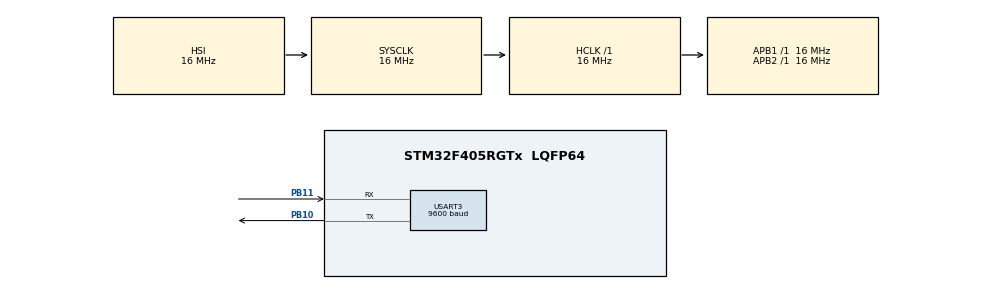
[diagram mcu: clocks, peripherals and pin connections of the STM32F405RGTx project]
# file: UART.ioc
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Mcu.Family=STM32F4
Mcu.Name=STM32F405RGTx
Mcu.Package=LQFP64
NVIC.PriorityGroup=NVIC_PRIORITYGROUP_4
NVIC.USART3_IRQn=true\:0\:0\:false\:false\:true\:true\:true\:true
PA13.Mode=Serial_Wire
PA13.Signal=SYS_JTMS-SWDIO
PA14.Mode=Serial_Wire
PA14.Signal=SYS_JTCK-SWCLK
PB10.Mode=Asynchronous
PB10.Signal=USART3_TX
PB11.Mode=Asynchronous
PB11.Signal=USART3_RX
ProjectManager.HeapSize=0x200
ProjectManager.StackSize=0x400
ProjectManager.TargetToolchain=STM32CubeIDE
RCC.AHBFreq_Value=16000000
RCC.APB1Freq_Value=16000000
RCC.APB2Freq_Value=16000000
RCC.CortexFreq_Value=16000000
RCC.HSE_VALUE=25000000
RCC.HSI_VALUE=16000000
RCC.LSE_VALUE=32768
RCC.SYSCLKFreq_VALUE=16000000
RCC.VCOOutputFreq_Value=192000000
USART3.BaudRate=9600
USART3.VirtualMode=VM_ASYNC
board=custom

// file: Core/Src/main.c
/* USER CODE BEGIN Header */
/**
 ******************************************************************************
 * @file           : main.c
 * @brief          : Main program body
 ******************************************************************************
 * @attention
 *
 * Copyright (c) 2022 STMicroelectronics.
 * All rights reserved.
 *
 * This software is licensed under terms that can be found in the LICENSE file
 * in the root directory of this software component.
 * If no LICENSE file comes with this software, it is provided AS-IS.
 *
 ******************************************************************************
 */
/* USER CODE END Header */
#include "main.h"

/* USER CODE BEGIN Includes */
uint8_t u8_RxBuff[20];
uint8_t u8_RxData;
uint8_t u8_TxBuff[20] = "Running...";
uint8_t _rxIndex;
uint16_t Tx_Flag = 0;
/* USER CODE END Includes */

UART_HandleTypeDef huart3;

/* USER CODE BEGIN PV */
#ifdef __GNUC__
/* With GCC/RAISONANCE, small printf (option LD Linker->Libraries->Small printf
 set to 'Yes') calls __io_putchar() */
#define PUTCHAR_PROTOTYPE int __io_putchar(int ch)
#else
 #define PUTCHAR_PROTOTYPE int fputc(int ch, FILE *f)
#endif /* __GNUC__ */

/**
 * @brief Retargets the C library printf function to the USART.
 * @param None
 * @retval None
 */
PUTCHAR_PROTOTYPE
{
  /* Place your implementation of fputc here */
  /* e.g. write a character to the USART */
  HAL_UART_Transmit(&huart3, (uint8_t*) &ch, 1, 100);
  return ch;
}

/* USER CODE END PV */

void SystemClock_Config(void);
static void MX_GPIO_Init(void);
static void MX_USART3_UART_Init(void);

/* USER CODE BEGIN 0 */
void HAL_UART_RxCpltCallback(UART_HandleTypeDef *huart)
{
  /* Prevent unused argument(s) compilation warning */
  UNUSED(huart);
//  if(huart->Instance == USART3)
  {
	  if(u8_RxData != 13)
	  {
		  u8_RxBuff[_rxIndex++] = u8_RxData;
	  }
	  else if(u8_RxData == 13)
	  {
		  _rxIndex = 0;
		  Tx_Flag = 1;
	  }
	  HAL_UART_Receive_IT(&huart3, &u8_RxData, 1);
  }
  /* NOTE: This function should not be modified, when the callback is needed,
           the HAL_UART_RxCpltCallback could be implemented in the user file
   */

}
/* USER CODE END 0 */

int main(void)
{

  /* MCU Configuration--------------------------------------------------------*/

  /* Reset of all peripherals, Initializes the Flash interface and the Systick. */
  HAL_Init();

  /* Configure the system clock */
  SystemClock_Config();

  /* Initialize all configured peripherals */
  MX_GPIO_Init();
  MX_USART3_UART_Init();
  /* USER CODE BEGIN 2 */
  HAL_UART_Transmit(&huart3, u8_TxBuff, sizeof(u8_TxBuff), 100);
  HAL_UART_Receive_IT(&huart3, &u8_RxData, 1);
  /* USER CODE END 2 */

  /* Infinite loop */
	while (1) {

    /* USER CODE BEGIN 3 */
		if(Tx_Flag)
		{
			for(int i=0; i< 20; i++)
			{
				u8_RxBuff[i] = u8_RxBuff[i];

			}
			HAL_UART_Transmit(&huart3, u8_TxBuff, sizeof(u8_TxBuff), 100);
			Tx_Flag = 0;
		}
	}
  /* USER CODE END 3 */
}

void SystemClock_Config(void)
{
  RCC_OscInitTypeDef RCC_OscInitStruct = {0};
  RCC_ClkInitTypeDef RCC_ClkInitStruct = {0};

  /** Configure the main internal regulator output voltage
  */
  __HAL_RCC_PWR_CLK_ENABLE();
  __HAL_PWR_VOLTAGESCALING_CONFIG(PWR_REGULATOR_VOLTAGE_SCALE1);

  /** Initializes the RCC Oscillators according to the specified parameters
  * in the RCC_OscInitTypeDef structure.
  */
  RCC_OscInitStruct.OscillatorType = RCC_OSCILLATORTYPE_HSI;
  RCC_OscInitStruct.HSIState = RCC_HSI_ON;
  RCC_OscInitStruct.HSICalibrationValue = RCC_HSICALIBRATION_DEFAULT;
  RCC_OscInitStruct.PLL.PLLState = RCC_PLL_NONE;
  if (HAL_RCC_OscConfig(&RCC_OscInitStruct) != HAL_OK)
  {
    Error_Handler();
  }

  /** Initializes the CPU, AHB and APB buses clocks
  */
  RCC_ClkInitStruct.ClockType = RCC_CLOCKTYPE_HCLK|RCC_CLOCKTYPE_SYSCLK
                              |RCC_CLOCKTYPE_PCLK1|RCC_CLOCKTYPE_PCLK2;
  RCC_ClkInitStruct.SYSCLKSource = RCC_SYSCLKSOURCE_HSI;
  RCC_ClkInitStruct.AHBCLKDivider = RCC_SYSCLK_DIV1;
  RCC_ClkInitStruct.APB1CLKDivider = RCC_HCLK_DIV1;
  RCC_ClkInitStruct.APB2CLKDivider = RCC_HCLK_DIV1;

  if (HAL_RCC_ClockConfig(&RCC_ClkInitStruct, FLASH_LATENCY_0) != HAL_OK)
  {
    Error_Handler();
  }
}

static void MX_USART3_UART_Init(void)
{

  huart3.Instance = USART3;
  huart3.Init.BaudRate = 9600;
  huart3.Init.WordLength = UART_WORDLENGTH_8B;
  huart3.Init.StopBits = UART_STOPBITS_1;
  huart3.Init.Parity = UART_PARITY_NONE;
  huart3.Init.Mode = UART_MODE_TX_RX;
  huart3.Init.HwFlowCtl = UART_HWCONTROL_NONE;
  huart3.Init.OverSampling = UART_OVERSAMPLING_16;
  if (HAL_UART_Init(&huart3) != HAL_OK)
  {
    Error_Handler();
  }

}

static void MX_GPIO_Init(void)
{

  /* GPIO Ports Clock Enable */
  __HAL_RCC_GPIOB_CLK_ENABLE();
  __HAL_RCC_GPIOA_CLK_ENABLE();

}

void Error_Handler(void)
{
	__disable_irq();
	while (1) {
	}
}
